# ELM register map
Vendor: Texas Instruments
Peripheral module from a debugger description file (folder TDA2Px).
Registers are 32-bit, read-only, reset 0x0 unless marked. A register's access mark holds for its fields unless they carry their own. Offsets are as the file gives them; lines under a group give offsets from that group; [hi:lo] are bit positions; {n}, {i} and the like mark numbered series; 'fields as' and 'values as' point back to an identical list; <NAME> marks a mode.

## ELM
0x00 ELM_REVISION reset not defined — This register contains the IP revision code. (A write or reset of to this register has no effect.)
  [31:0] REVISION — IP Revision (TI internal data)
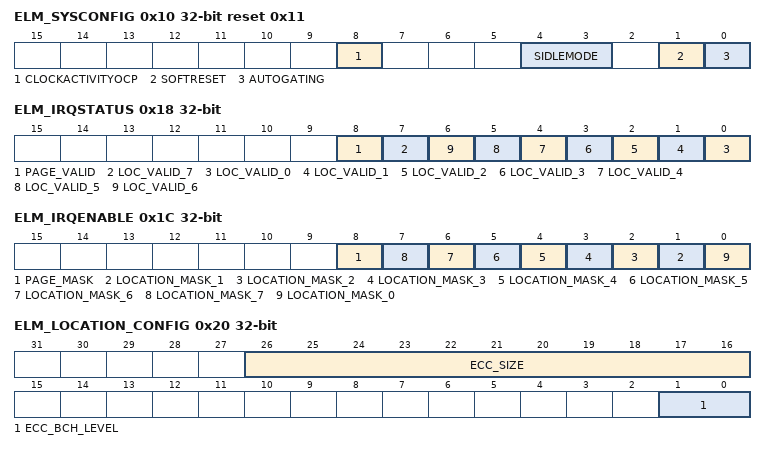
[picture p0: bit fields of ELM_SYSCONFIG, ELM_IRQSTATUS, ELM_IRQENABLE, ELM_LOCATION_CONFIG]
0x10 ELM_SYSCONFIG access per field reset 0x11 — This register allows controlling various parameters of the OCP interface.
  [8] CLOCKACTIVITYOCP rw — OCP clock activity when module is in IDLE mode (during wake-up mode period)
    0=OCP_OFF (OCP clock can be switched off.); 1=OCP_ON (OCP clock is maintained during wake-up period.)
  [4:3] SIDLEMODE rw — Slave interface power management (IDLE req/ack control)
    0=FORCE_IDLE (Force-idle. IDLE request is acknowledged unconditionally and immediately (Default Dumb mode for safety)); 1=NO_IDLE (No-idle. IDLE request is never acknowledged.); 2=SMART_IDLE (Smart-idle. The acknowledgment to an IDLE request is given based on the internal activity.)
  [1] SOFTRESET rw — Module software reset This bit is automatically reset by hardware (during reads, it always returns 0). It has same effect as the OCP hardware reset.
    0=NORMAL (Normal mode); 1=RESET (Start soft reset sequence.)
  [0] AUTOGATING rw — Internal OCP clock gating strategy (no module visible effect other than saving power)
    0=OCP_FREE (OCP clock is free-running.); 1=OCP_GATING (Automatic internal OCP clock gating strategy is applied based on the OCP interface activity.)
0x14 ELM_SYSSTATUS reset 0x1 — Internal reset monitoring (OCP domain) Undefined since: From hardware perspective, the reset state is 0. From software user perspective, when the accessible module is 1.
  [0] RESETDONE
    0=RST_ONGOING (Reset is ongoing.); 1=RST_DONE (Reset is done (completed).)
0x18 ELM_IRQSTATUS access not given — Interrupt status. This register doubles as a status register for the error-location processes.
  [8] PAGE_VALID rw — Error-location status for a full page, based on the mask definition Read 0x0: Error locations invalid for all polynomials enabled in the ECC_INTERRUPT_MASK register Read 0x1: All error locations valid Write 0x0: No effect Write 0x1: Clear interrupt
  [7] LOC_VALID_7 — Error-location status for syndrome polynomial 7 Read 0x0: No syndrome processed or process in progress Read 0x1: Error-location process completed Write 0x0: No effect Write 0x1: Clear interrupt (access RW W1toClr)
  [n] LOC_VALID_{n} (n=0..6) — Error-location status for syndrome polynomial {n} (access RW W1toClr)
0x1C ELM_IRQENABLE access per field — Interrupt enable
  [8] PAGE_MASK rw — Page interrupt mask bit 0: Disable interrupt 1: Enable interrupt
  [n] LOCATION_MASK_{n} rw (n=1..7) — Error-location interrupt mask bit for syndrome polynomial {n}
  [0] LOCATION_MASK_0 rw — Error-location interrupt mask bit for syndrome polynomial 0 0: Disable interrupt 1: Enable interrupt
0x20 ELM_LOCATION_CONFIG access per field — ECC algorithm parameters
  [26:16] ECC_SIZE rw — Maximum size of the buffers for which the error-location engine is used, in number of nibbles (4-bit entities)
  [1:0] ECC_BCH_LEVEL rw — Error correction level 0x0: 4 bits 0x1: 8 bits 0x2: 16 bits 0x3: Reserved
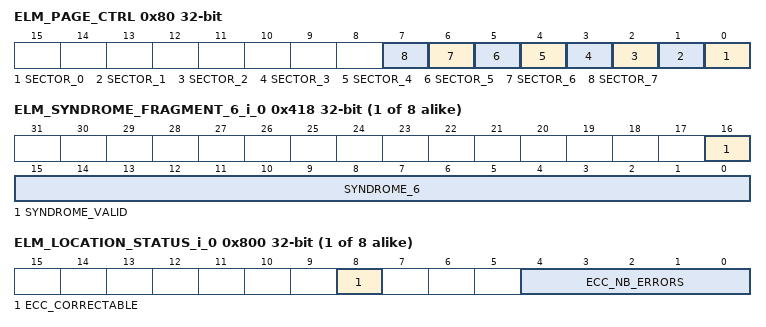
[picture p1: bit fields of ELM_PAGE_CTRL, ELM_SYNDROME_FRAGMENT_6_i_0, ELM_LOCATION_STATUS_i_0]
0x80 ELM_PAGE_CTRL access per field — Page definition
  [n] SECTOR_{n} rw (n=0..7) — Set to 1 if syndrome polynomial {n} is part of the page in page mode. Must be 0 in continuous mode.
{0x400+0x40*i} ELM_SYNDROME_FRAGMENT_0_i_{i} rw (i=0..7) — Input syndrome polynomial bits 0 to 31.
  [31:0] SYNDROME_0 — Syndrome bits 0 to 31
{0x404+0x40*i} ELM_SYNDROME_FRAGMENT_1_i_{i} rw (i=0..7) — Input syndrome polynomial bits 32 to 63.
  [31:0] SYNDROME_1 — Syndrome bits 32 to 63
{0x408+0x40*i} ELM_SYNDROME_FRAGMENT_2_i_{i} rw (i=0..7) — Input syndrome polynomial bits 64 to 95.
  [31:0] SYNDROME_2 — Syndrome bits 64 to 95
{0x40C+0x40*i} ELM_SYNDROME_FRAGMENT_3_i_{i} rw (i=0..7) — Input syndrome polynomial bits 96 to 127
  [31:0] SYNDROME_3 — Syndrome bits 96 to 127
{0x410+0x40*i} ELM_SYNDROME_FRAGMENT_4_i_{i} rw (i=0..7) — Input syndrome polynomial bits 128 to 159.
  [31:0] SYNDROME_4 — Syndrome bits 128 to 159
{0x414+0x40*i} ELM_SYNDROME_FRAGMENT_5_i_{i} rw (i=0..7) — Input syndrome polynomial bits 160 to 191.
  [31:0] SYNDROME_5 — Syndrome bits 160 to 191
{0x418+0x40*i} ELM_SYNDROME_FRAGMENT_6_i_{i} access per field (i=0..7) — Input syndrome polynomial bits 192 to 207.
  [16] SYNDROME_VALID rw — Syndrome valid bit 0x0: This syndrome polynomial must not be processed. 0x1: This syndrome polynomial must be processed.
  [15:0] SYNDROME_6 rw — Syndrome bits 192 to 207
{0x800+0x100*i} ELM_LOCATION_STATUS_i_{i} (i=0..7) — Exit status for the syndrome polynomial processing
  [8] ECC_CORRECTABLE — Error-location process exit status 0x0: ECC error-location process failed. Number of errors and error locations are invalid. 0x1: All errors were successfully located. Number of errors and error locations are valid.
  [4:0] ECC_NB_ERRORS — Number of errors detected and located
{0x880+4i} ELM_ERROR_LOCATION_{i}_i_0 (i=0..15) — Error-location register
  [12:0] ECC_ERROR_LOCATION — Error-location bit address
{0x980+4i} ELM_ERROR_LOCATION_{i}_i_1 (i=0..15) — Error-location register
  [12:0] ECC_ERROR_LOCATION — Error-location bit address
{0xA80+4i} ELM_ERROR_LOCATION_{i}_i_2 (i=0..15) — Error-location register
  [12:0] ECC_ERROR_LOCATION — Error-location bit address
{0xB80+4i} ELM_ERROR_LOCATION_{i}_i_3 (i=0..15) — Error-location register
  [12:0] ECC_ERROR_LOCATION — Error-location bit address
{0xC80+4i} ELM_ERROR_LOCATION_{i}_i_4 (i=0..15) — Error-location register
  [12:0] ECC_ERROR_LOCATION — Error-location bit address
{0xD80+4i} ELM_ERROR_LOCATION_{i}_i_5 (i=0..15) — Error-location register
  [12:0] ECC_ERROR_LOCATION — Error-location bit address
{0xE80+4i} ELM_ERROR_LOCATION_{i}_i_6 (i=0..15) — Error-location register
  [12:0] ECC_ERROR_LOCATION — Error-location bit address
{0xF80+4i} ELM_ERROR_LOCATION_{i}_i_7 (i=0..15) — Error-location register
  [12:0] ECC_ERROR_LOCATION — Error-location bit address
